# STMP3770 register map
Vendor: Freescale Semiconductor (NXP); Series: STMP37xx; File version: 1.0
CPU: other r0p0, little endian, no MPU, no FPU, 2 interrupt priority bits
Registers are 32-bit, read-write, reset 0x0 unless marked. A register's access mark holds for its fields unless they carry their own. Offsets are from the block's base; [hi:lo] are bit positions.

## IR — 红外接口控制器(IrDA/红外收发)
Base 0x80078000
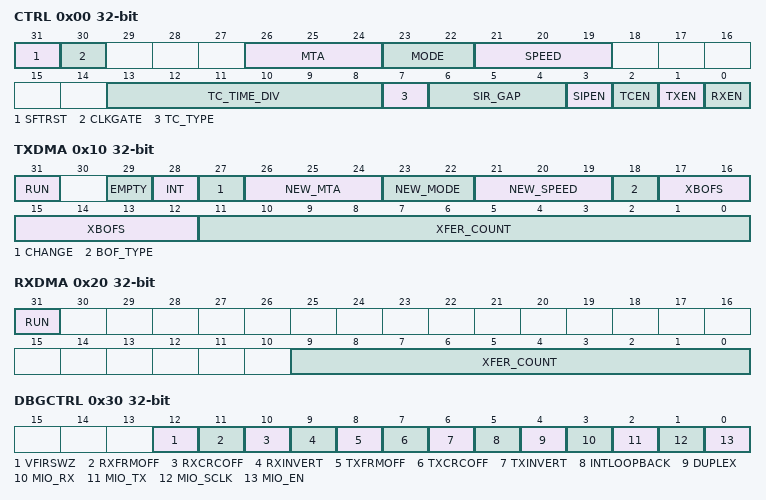
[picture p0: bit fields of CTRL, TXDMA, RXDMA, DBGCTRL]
0x00 CTRL — IR Control Register
  [31] SFTRST — 软复位控制位，写1复位本模块，写0恢复正常运行。复位后所有寄存器回到默认值。
    0=RUN; 1=RESET
  [30] CLKGATE — 时钟门控控制位，写1关闭模块时钟以节省功耗，配置状态保持。写0恢复正常时钟供应。
  [26:24] MTA — 最小时间间隙配置。
    0=MTA_10MS; 1=MTA_5MS; 2=MTA_1MS; 3=MTA_500US; 4=MTA_100US; 5=MTA_50US; 6=MTA_10US; 7=MTA_0
  [23:22] MODE — 红外工作模式选择。
    0=SIR; 1=MIR; 2=FIR; 3=VFIR
  [21:19] SPEED — 红外通信速率选择（SIR/MIR/FIR）。
    0=SPD000; 1=SPD001; 2=SPD010; 3=SPD011; 4=SPD100; 5=SPD101
  [13:8] TC_TIME_DIV — 定时器/计数器分频配置。
  [7] TC_TYPE — 定时器/计数器类型选择。
  [6:4] SIR_GAP — SIR帧间间隔控制，配置串行红外帧之间的空闲时间。
    0=GAP_10K; 1=GAP_5K; 2=GAP_1K; 3=GAP_500; 4=GAP_100; 5=GAP_50; 6=GAP_10; 7=GAP_0
  [3] SIPEN — SIP模式使能，置位时启用串行红外协议。
  [2] TCEN — 红外定时器/计数器使能。
  [1] TXEN — 红外发送使能，置位时启用红外发送器。
  [0] RXEN — 红外接收使能，置位时启用红外接收器。
0x10 TXDMA — IR Transmit DMA Control Register
  [31] RUN — 运行使能位，写1启动模块运行，写0停止。DMA操作时硬件自动置位。
  [29] EMPTY — DMA缓冲区空标志。
  [28] INT — 内部帧传输指示。
  [27] CHANGE — 速率/模式/MTA变更使能。
  [26:24] NEW_MTA — 下一帧使用的新MTA值。
  [23:22] NEW_MODE — 下一帧使用的新模式。
  [21:19] NEW_SPEED — 下一帧使用的新速率。
  [18] BOF_TYPE — 帧起始类型选择。
  [17:12] XBOFS — 发送DMA缓冲区偏移量。
  [11:0] XFER_COUNT — 数据传送计数字段，指定本次DMA/传输操作的数据量，单位为字（由WORD_LENGTH决定字宽）。
0x20 RXDMA — IR Receive DMA Register
  [31] RUN — 运行使能位，写1启动模块运行，写0停止。DMA操作时硬件自动置位。
  [9:0] XFER_COUNT — 数据传送计数字段，指定本次DMA/传输操作的数据量，单位为字（由WORD_LENGTH决定字宽）。
0x30 DBGCTRL — IR Debug Control Register
  [12] VFIRSWZ — VFIR软件交换控制。
    0=NORMAL; 1=SWAP
  [11] RXFRMOFF — 接收帧封装关闭。
  [10] RXCRCOFF — 接收CRC关闭。
  [9] RXINVERT — 接收数据极性反转。
  [8] TXFRMOFF — 发送帧封装关闭。
  [7] TXCRCOFF — 发送CRC关闭。
  [6] TXINVERT — 发送数据极性反转。
  [5] INTLOOPBACK — 内部环回使能，用于自测。
  [4] DUPLEX — 全双工模式使能。
  [3] MIO_RX — MIO接收数据观察。
  [2] MIO_TX — MIO发送数据观察。
  [1] MIO_SCLK — MIO串行时钟选择。
  [0] MIO_EN — 多功能I/O使能。
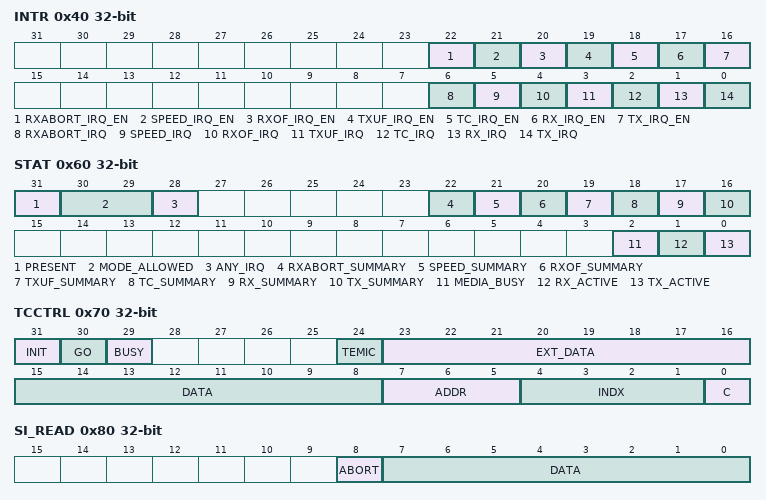
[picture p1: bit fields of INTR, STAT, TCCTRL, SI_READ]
0x40 INTR — IR Interrupt Register
  [22] RXABORT_IRQ_EN — 接收中止中断使能。
    0=DISABLED; 1=ENABLED
  [21] SPEED_IRQ_EN — 速率变更中断使能。
    0=DISABLED; 1=ENABLED
  [20] RXOF_IRQ_EN — 接收上溢中断使能。
    0=DISABLED; 1=ENABLED
  [19] TXUF_IRQ_EN — 发送下溢中断使能。
    0=DISABLED; 1=ENABLED
  [18] TC_IRQ_EN — 定时器/计数器中断使能。
    0=DISABLED; 1=ENABLED
  [17] RX_IRQ_EN — 接收中断使能。
    0=DISABLED; 1=ENABLED
  [16] TX_IRQ_EN — 发送中断使能。
    0=DISABLED; 1=ENABLED
  [6] RXABORT_IRQ — 接收中止中断状态，写1清零。
    0=NO_REQUEST; 1=REQUEST
  [5] SPEED_IRQ — 速率变更中断状态，写1清零。
    0=NO_REQUEST; 1=REQUEST
  [4] RXOF_IRQ — 接收上溢中断状态，写1清零。
    0=NO_REQUEST; 1=REQUEST
  [3] TXUF_IRQ — 发送下溢中断状态，写1清零。
    0=NO_REQUEST; 1=REQUEST
  [2] TC_IRQ — 定时器/计数器中断状态，写1清零。
    0=NO_REQUEST; 1=REQUEST
  [1] RX_IRQ — 接收中断状态，写1清零。
    0=NO_REQUEST; 1=REQUEST
  [0] TX_IRQ — 发送中断状态，写1清零。
    0=NO_REQUEST; 1=REQUEST
0x50 DATA — IR RX Data Register
  [31:0] DATA — 数据寄存器，写操作将数据写入发送FIFO，读操作从接收FIFO取出数据。
0x60 STAT — IR Status Register
  [31] PRESENT — IR模块存在标志，只读。1=存在。
    0=UNAVAILABLE; 1=AVAILABLE
  [30:29] MODE_ALLOWED — 当前允许的模式指示。
    0=VFIR; 1=FIR; 2=MIR; 3=SIR
  [28] ANY_IRQ — 任意中断汇总标志。
    0=NO_REQUEST; 1=REQUEST
  [22] RXABORT_SUMMARY — 接收中止中断汇总。
    0=NO_REQUEST; 1=REQUEST
  [21] SPEED_SUMMARY — 速率变更中断汇总。
    0=NO_REQUEST; 1=REQUEST
  [20] RXOF_SUMMARY — 接收上溢中断汇总。
    0=NO_REQUEST; 1=REQUEST
  [19] TXUF_SUMMARY — 发送下溢中断汇总。
    0=NO_REQUEST; 1=REQUEST
  [18] TC_SUMMARY — 定时器/计数器中断汇总。
    0=NO_REQUEST; 1=REQUEST
  [17] RX_SUMMARY — 接收中断汇总。
    0=NO_REQUEST; 1=REQUEST
  [16] TX_SUMMARY — 发送中断汇总。
    0=NO_REQUEST; 1=REQUEST
  [2] MEDIA_BUSY — 介质忙状态。
  [1] RX_ACTIVE — 接收器激活状态。
  [0] TX_ACTIVE — 发送器激活状态。
0x70 TCCTRL — IR Transceiver Control Register
  [31] INIT — 初始化控制。
  [30] GO — 启动控制。
  [29] BUSY — 定时器忙标志。
  [24] TEMIC — TEMIC协议控制。
    0=LOW; 1=HIGH
  [23:16] EXT_DATA — 外部数据。
  [15:8] DATA — 数据寄存器，写操作将数据写入发送FIFO，读操作从接收FIFO取出数据。
  [7:5] ADDR — 定时器/计数器地址。
  [4:1] INDX — 定时器/计数器索引。
  [0] C — 定时器/计数器计数值。
0x80 SI_READ — IR Serial Interface Read Data Register
  [8] ABORT — SI读中止。
  [7:0] DATA — 数据寄存器，写操作将数据写入发送FIFO，读操作从接收FIFO取出数据。
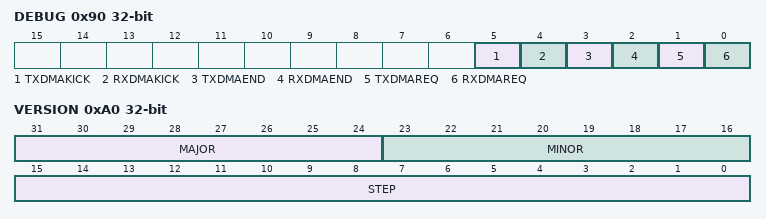
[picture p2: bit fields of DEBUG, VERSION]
0x90 DEBUG ro — IR Debug Register
  [5] TXDMAKICK — 发送DMA触发。
  [4] RXDMAKICK — 接收DMA触发。
  [3] TXDMAEND — 发送DMA结束。
  [2] RXDMAEND — 接收DMA结束。
  [1] TXDMAREQ — 发送DMA请求状态。
  [0] RXDMAREQ — 接收DMA请求状态。
0xA0 VERSION ro — IR Version Register
  [31:24] MAJOR — IR模块主版本号，只读。
  [23:16] MINOR — IR模块次版本号，只读。
  [15:0] STEP — IR模块修订步进号，只读。
